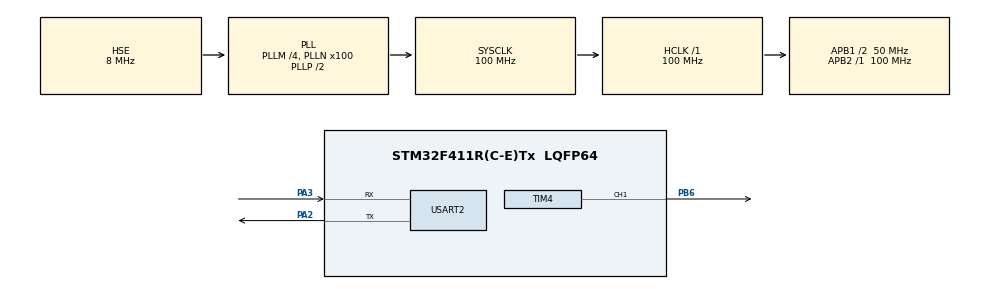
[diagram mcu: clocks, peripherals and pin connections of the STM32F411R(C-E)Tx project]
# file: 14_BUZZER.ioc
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Mcu.Family=STM32F4
Mcu.Name=STM32F411R(C-E)Tx
Mcu.Package=LQFP64
NVIC.PriorityGroup=NVIC_PRIORITYGROUP_4
NVIC.USART2_IRQn=true\:0\:0\:false\:false\:true\:true\:true\:true
PA13.Mode=Serial_Wire
PA13.Signal=SYS_JTMS-SWDIO
PA14.Mode=Serial_Wire
PA14.Signal=SYS_JTCK-SWCLK
PA2.Mode=Asynchronous
PA2.Signal=USART2_TX
PA3.Mode=Asynchronous
PA3.Signal=USART2_RX
PB6.Signal=S_TIM4_CH1
PH0\ -\ OSC_IN.Mode=HSE-External-Oscillator
PH0\ -\ OSC_IN.Signal=RCC_OSC_IN
PH1\ -\ OSC_OUT.Mode=HSE-External-Oscillator
PH1\ -\ OSC_OUT.Signal=RCC_OSC_OUT
ProjectManager.HeapSize=0x200
ProjectManager.StackSize=0x400
ProjectManager.TargetToolchain=STM32CubeIDE
RCC.48MHZClocksFreq_Value=50000000
RCC.AHBFreq_Value=100000000
RCC.APB1CLKDivider=RCC_HCLK_DIV2
RCC.APB1Freq_Value=50000000
RCC.APB1TimFreq_Value=100000000
RCC.APB2Freq_Value=100000000
RCC.APB2TimFreq_Value=100000000
RCC.CortexFreq_Value=100000000
RCC.HCLKFreq_Value=100000000
RCC.HSE_VALUE=8000000
RCC.HSI_VALUE=16000000
RCC.LSE_VALUE=32768
RCC.PLLM=4
RCC.PLLN=100
RCC.PLLSourceVirtual=RCC_PLLSOURCE_HSE
RCC.SYSCLKFreq_VALUE=100000000
RCC.SYSCLKSource=RCC_SYSCLKSOURCE_PLLCLK
RCC.VCOOutputFreq_Value=200000000
SH.S_TIM4_CH1.0=TIM4_CH1,PWM Generation1 CH1
TIM4.Channel-PWM\ Generation1\ CH1=TIM_CHANNEL_1
TIM4.Period=1000-1
TIM4.Prescaler=2000-1
USART2.VirtualMode=VM_ASYNC
VP_TIM4_VS_ClockSourceINT.Mode=Internal
board=custom

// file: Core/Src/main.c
/* USER CODE BEGIN Header */
/**
  ******************************************************************************
  * @file           : main.c
  * @brief          : Main program body
  ******************************************************************************
  * @attention
  *
  * Copyright (c) 2025 STMicroelectronics.
  * All rights reserved.
  *
  * This software is licensed under terms that can be found in the LICENSE file
  * in the root directory of this software component.
  * If no LICENSE file comes with this software, it is provided AS-IS.
  *
  ******************************************************************************
  */
/* USER CODE END Header */
#include "main.h"
#include "tim.h"
#include "usart.h"
#include "gpio.h"

/* USER CODE BEGIN PD */
#define Do  		383
#define Re  		340
#define Mi  		304
#define Fa  		286
#define Sol 		255
#define Ra  		227
#define Si  		203
#define DDo 		191
#define Note_16 	100
#define Note_8 	200
#define Note_4 	400
#define Note_2 	800
#define Note_w 	1600

typedef enum {
	IDLE,
	PLAYING
} PLAYBACKSTATE;
/* USER CODE END PD */

/* USER CODE BEGIN PV */
uint8_t rxData[1];

uint16_t SchoolBell[] = {Do, Mi, Sol, Do, Mi, Sol, Ra, Ra, Ra, Sol, Fa, Fa, Fa, Mi, Mi, Mi, Re, Re, Re, Do};
//uint16_t song[] = {Do, Mi, Sol, Do, Mi, Sol, Ra, Ra, Ra, Sol, Fa, Fa, Fa, Mi, Mi, Mi, Re, Re, Re, Do};
uint16_t time[] = {};

static PLAYBACKSTATE playBackState = IDLE;
static uint32_t lastTick = 0;
static uint32_t delayStart = 0;
static uint16_t i = 0;
static uint8_t rxCommand = 0;
/* USER CODE END PV */

void SystemClock_Config(void);
/* USER CODE BEGIN PFP */
void HAL_UART_RxCpltCallback(UART_HandleTypeDef *huart) {
	HAL_UART_Receive_IT(&huart2, rxData, sizeof(rxData));

	rxCommand = rxData[0];
	playBackState = (rxCommand == 'a' || rxCommand == 'b') ? PLAYING : IDLE;
	i = 0;
	lastTick = HAL_GetTick();
	delayStart = HAL_GetTick();
	HAL_TIM_PWM_Start(&htim4, TIM_CHANNEL_1);
}

void updatePlayBack() {
	uint32_t currTick = HAL_GetTick();

	if(playBackState == PLAYING) {
		if(rxCommand == 'a') {
			// 20ms 마다 TIM4->PSC , TIM4->CCR1 업데이트
			if((currTick - lastTick) >= 20 && i < (sizeof(SchoolBell)/sizeof(SchoolBell[0]))) {
				TIM4->PSC = SchoolBell[i];
				TIM4->CCR1 = 300;
				lastTick = currTick;
			}

			// 600ms 가 지난후에 다음 음으로 이동
			if((currTick - delayStart) >= 600 && i < (sizeof(SchoolBell)/sizeof(SchoolBell[0]))) {
				i++;
				delayStart = currTick;
			}

			// 모든 음을 재생한 후에 상태를 IDLE로 바꿈
			if(i >= (sizeof(SchoolBell)/sizeof(SchoolBell[0]))) {
				playBackState = IDLE;
				HAL_TIM_PWM_Stop(&htim4, TIM_CHANNEL_1);
			}
		}
		else if(rxCommand == 'b')
		{
			//HAL_TIM_PWM_Start(&htim4, TIM_CHANNEL_1);
			if((currTick - lastTick) >= 20 && i < (sizeof(SchoolBell)/sizeof(SchoolBell[0]))) {
				TIM4->PSC = SchoolBell[i];
				TIM4->CCR1 = 300;
				lastTick = currTick;
			}

			// 600ms 가 지난후에 다음 음으로 이동
			if((currTick - delayStart) >= 600 && i < (sizeof(SchoolBell)/sizeof(SchoolBell[0]))) {
				i++;
				delayStart = currTick;
			}

			// 모든 음을 재생한 후에 상태를 IDLE로 바꿈
			if(i >= (sizeof(SchoolBell)/sizeof(SchoolBell[0]))) {
				playBackState = IDLE;
				HAL_TIM_PWM_Stop(&htim4, TIM_CHANNEL_1);
			}
		}
	}
}
/* USER CODE END PFP */

int main(void)
{

  /* MCU Configuration--------------------------------------------------------*/

  /* Reset of all peripherals, Initializes the Flash interface and the Systick. */
  HAL_Init();

  /* Configure the system clock */
  SystemClock_Config();

  /* Initialize all configured peripherals */
  MX_GPIO_Init();
  MX_USART2_UART_Init();
  MX_TIM4_Init();
  /* USER CODE BEGIN 2 */
//  HAL_TIM_PWM_Start(&htim4, TIM_CHANNEL_1);
  HAL_UART_Receive_IT(&huart2, rxData, sizeof(rxData));
  /* USER CODE END 2 */

  /* Infinite loop */
  /* USER CODE BEGIN WHILE */
  while (1)
  {
	  updatePlayBack();
	  HAL_Delay(1);

//	  TIM4->PSC = 383;		// Do
//	  HAL_Delay(500);
//	  TIM4->CCR1 = 0;
//	  HAL_Delay(10);
//	  TIM4->CCR1 = 500;
//
//	  TIM4->PSC = 303;		// Mi
//	  HAL_Delay(500);
//	  TIM4->CCR1 = 0;
//	  HAL_Delay(10);
//	  TIM4->CCR1 = 500;
//
//	  TIM4->PSC = 255;		// Sol
//	  HAL_Delay(500);
//	  TIM4->CCR1 = 0;
//	  HAL_Delay(10);
//	  TIM4->CCR1 = 500;
    /* USER CODE END WHILE */

  }
}

void SystemClock_Config(void)
{
  RCC_OscInitTypeDef RCC_OscInitStruct = {0};
  RCC_ClkInitTypeDef RCC_ClkInitStruct = {0};

  /** Configure the main internal regulator output voltage
  */
  __HAL_RCC_PWR_CLK_ENABLE();
  __HAL_PWR_VOLTAGESCALING_CONFIG(PWR_REGULATOR_VOLTAGE_SCALE1);

  /** Initializes the RCC Oscillators according to the specified parameters
  * in the RCC_OscInitTypeDef structure.
  */
  RCC_OscInitStruct.OscillatorType = RCC_OSCILLATORTYPE_HSE;
  RCC_OscInitStruct.HSEState = RCC_HSE_ON;
  RCC_OscInitStruct.PLL.PLLState = RCC_PLL_ON;
  RCC_OscInitStruct.PLL.PLLSource = RCC_PLLSOURCE_HSE;
  RCC_OscInitStruct.PLL.PLLM = 4;
  RCC_OscInitStruct.PLL.PLLN = 100;
  RCC_OscInitStruct.PLL.PLLP = RCC_PLLP_DIV2;
  RCC_OscInitStruct.PLL.PLLQ = 4;
  if (HAL_RCC_OscConfig(&RCC_OscInitStruct) != HAL_OK)
  {
    Error_Handler();
  }

  /** Initializes the CPU, AHB and APB buses clocks
  */
  RCC_ClkInitStruct.ClockType = RCC_CLOCKTYPE_HCLK|RCC_CLOCKTYPE_SYSCLK
                              |RCC_CLOCKTYPE_PCLK1|RCC_CLOCKTYPE_PCLK2;
  RCC_ClkInitStruct.SYSCLKSource = RCC_SYSCLKSOURCE_PLLCLK;
  RCC_ClkInitStruct.AHBCLKDivider = RCC_SYSCLK_DIV1;
  RCC_ClkInitStruct.APB1CLKDivider = RCC_HCLK_DIV2;
  RCC_ClkInitStruct.APB2CLKDivider = RCC_HCLK_DIV1;

  if (HAL_RCC_ClockConfig(&RCC_ClkInitStruct, FLASH_LATENCY_3) != HAL_OK)
  {
    Error_Handler();
  }
}

void Error_Handler(void)
{
  __disable_irq();
  while (1)
  {
  }
}
